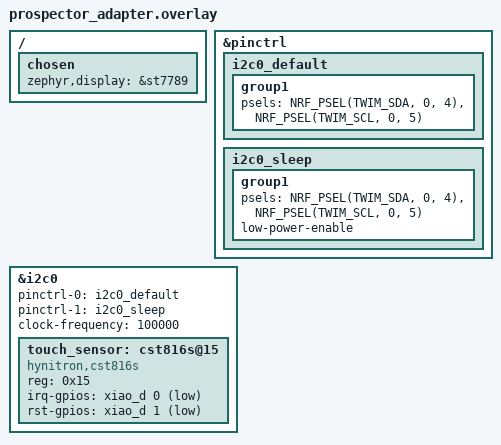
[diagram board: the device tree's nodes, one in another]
/ {
   chosen {
      zephyr,display = &st7789;
  };
};

/* This belongs to the shield overlay, so DT_HAS_HYNITRON_CST816S_ENABLED is
 * available while Kconfig resolves the receiver build. */
&pinctrl {
   i2c0_default: i2c0_default { group1 { psels = <NRF_PSEL(TWIM_SDA, 0, 4)>, <NRF_PSEL(TWIM_SCL, 0, 5)>; }; };
   i2c0_sleep: i2c0_sleep { group1 { psels = <NRF_PSEL(TWIM_SDA, 0, 4)>, <NRF_PSEL(TWIM_SCL, 0, 5)>; low-power-enable; }; };
};

&i2c0 {
   status = "okay";
   pinctrl-0 = <&i2c0_default>;
   pinctrl-1 = <&i2c0_sleep>;
   pinctrl-names = "default", "sleep";
   clock-frequency = <100000>;
   touch_sensor: cst816s@15 {
      compatible = "hynitron,cst816s";
      reg = <0x15>;
      status = "okay";
      irq-gpios = <&xiao_d 0 (GPIO_ACTIVE_LOW | GPIO_PULL_UP)>;
      rst-gpios = <&xiao_d 1 GPIO_ACTIVE_LOW>;
   };
};
